AUTOSAR XML (schema 4-2-2)
package /STELLANTIS/EPT/ASWCs
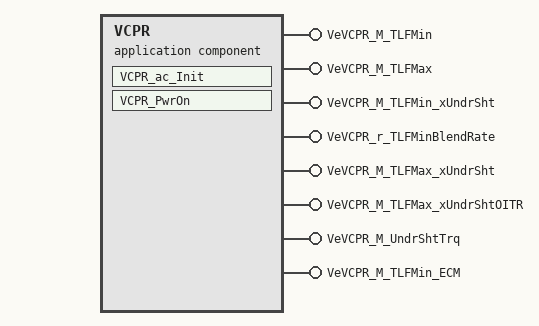
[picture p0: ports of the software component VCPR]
  application sw component type VCPR
    8 x provide port, all with nonqueued-sender-com-spec{data-element=Value, init-value=0}:
      VeVCPR_M_TLFMin: provided-interface=VeVCPR_M_TLFMin
      VeVCPR_M_TLFMax: provided-interface=VeVCPR_M_TLFMax
      VeVCPR_M_TLFMin_xUndrSht: provided-interface=VeVCPR_M_TLFMin_xUndrSht
      VeVCPR_r_TLFMinBlendRate: provided-interface=VeVCPR_r_TLFMinBlendRate
      VeVCPR_M_TLFMax_xUndrSht: provided-interface=VeVCPR_M_TLFMax_xUndrSht
      VeVCPR_M_TLFMax_xUndrShtOITR: provided-interface=VeVCPR_M_TLFMax_xUndrShtOITR
      VeVCPR_M_UndrShtTrq: provided-interface=VeVCPR_M_UndrShtTrq
      VeVCPR_M_TLFMin_ECM: provided-interface=VeVCPR_M_TLFMin_ECM
    behavior IB_VCPR: data-type-mapping=msADTtoIDTMapping, handle-termination-and-restart=NO-SUPPORT
      init event Event_VCPR_ac_Init: start-on-event=VCPR_ac_Init
      init event Event_PwrOn: start-on-event=VCPR_PwrOn
      runnable VCPR_ac_Init
        data-send-points:
          8 x access:
            OUT_VeVCPR_M_TLFMin_Value: accessed-variable=VeVCPR_M_TLFMin.Value
            OUT_VeVCPR_M_TLFMax_Value: accessed-variable=VeVCPR_M_TLFMax.Value
            OUT_VeVCPR_M_TLFMin_xUndrSht_Value: accessed-variable=VeVCPR_M_TLFMin_xUndrSht.Value
            OUT_VeVCPR_r_TLFMinBlendRate_Value: accessed-variable=VeVCPR_r_TLFMinBlendRate.Value
            OUT_VeVCPR_M_TLFMax_xUndrSht_Value: accessed-variable=VeVCPR_M_TLFMax_xUndrSht.Value
            OUT_VeVCPR_M_TLFMax_xUndrShtOITR_Value: accessed-variable=VeVCPR_M_TLFMax_xUndrShtOITR.Value
            OUT_VeVCPR_M_UndrShtTrq_Value: accessed-variable=VeVCPR_M_UndrShtTrq.Value
            OUT_VeVCPR_M_TLFMin_ECM_Value: accessed-variable=VeVCPR_M_TLFMin_ECM.Value
      runnable VCPR_PwrOn
        data-send-points:
          8 x access:
            OUT_VeVCPR_M_TLFMin_Value: accessed-variable=VeVCPR_M_TLFMin.Value
            OUT_VeVCPR_M_TLFMax_Value: accessed-variable=VeVCPR_M_TLFMax.Value
            OUT_VeVCPR_M_TLFMin_xUndrSht_Value: accessed-variable=VeVCPR_M_TLFMin_xUndrSht.Value
            OUT_VeVCPR_r_TLFMinBlendRate_Value: accessed-variable=VeVCPR_r_TLFMinBlendRate.Value
            OUT_VeVCPR_M_TLFMax_xUndrSht_Value: accessed-variable=VeVCPR_M_TLFMax_xUndrSht.Value
            OUT_VeVCPR_M_TLFMax_xUndrShtOITR_Value: accessed-variable=VeVCPR_M_TLFMax_xUndrShtOITR.Value
            OUT_VeVCPR_M_UndrShtTrq_Value: accessed-variable=VeVCPR_M_UndrShtTrq.Value
            OUT_VeVCPR_M_TLFMin_ECM_Value: accessed-variable=VeVCPR_M_TLFMin_ECM.Value
